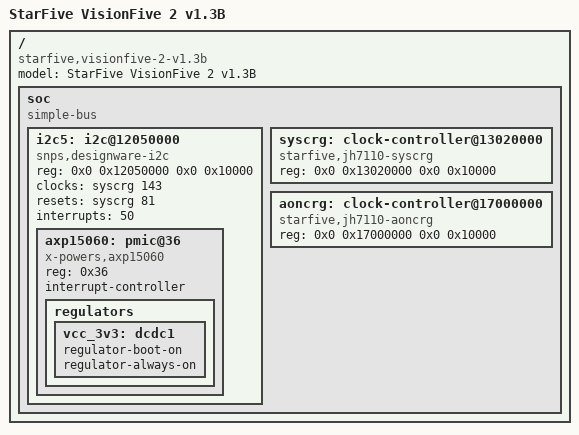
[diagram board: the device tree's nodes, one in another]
/dts-v1/;

/*
 * The PMIC's I2C bus **as mainline Linux describes it** (milestone 592
 * (radon's cold reboot dies in OpenSBI's PMIC write), provisional). NOT a dump
 * from any board: transcribed 2026-09-25 from arch/riscv/boot/dts/starfive/jh7110.dtsi (the bus,
 * `syscrg`, `aoncrg`) and jh7110-common.dtsi (the PMIC under `&i2c5`) on torvalds/linux master.
 * JH7110_SYSCLK_I2C5_APB is 143 and JH7110_SYSRST_I2C5_APB is 81 in mainline's
 * dt-bindings/{clock,reset}/starfive,jh7110-crg.h.
 *
 * The `pmic@36`'s `regulators` subtree is kept as one node so the walk has to close a grandchild
 * before the PMIC itself closes. `aoncrg` is present so a test can point at a provider that is a
 * clock controller and is not SYS (see `jh7110-pmic-bus-foreign.dts`).
 *
 * Regenerate with:
 *
 *     dtc -I dts -O dtb -o crates/machine_discovery/tests/fixtures/jh7110-pmic-bus-mainline.dtb \
 *                          crates/machine_discovery/tests/fixtures/jh7110-pmic-bus-mainline.dts
 */

/ {
	#address-cells = <2>;
	#size-cells = <2>;
	compatible = "starfive,visionfive-2-v1.3b", "starfive,jh7110";
	model = "StarFive VisionFive 2 v1.3B";

	soc {
		compatible = "simple-bus";
		#address-cells = <2>;
		#size-cells = <2>;
		ranges;

		i2c5: i2c@12050000 {
			compatible = "snps,designware-i2c";
			reg = <0x0 0x12050000 0x0 0x10000>;
			clocks = <&syscrg 143>;
			clock-names = "ref";
			resets = <&syscrg 81>;
			interrupts = <50>;
			#address-cells = <1>;
			#size-cells = <0>;
			status = "okay";

			axp15060: pmic@36 {
				compatible = "x-powers,axp15060";
				reg = <0x36>;
				interrupt-controller;
				#interrupt-cells = <1>;

				regulators {
					vcc_3v3: dcdc1 {
						regulator-boot-on;
						regulator-always-on;
					};
				};
			};
		};

		syscrg: clock-controller@13020000 {
			compatible = "starfive,jh7110-syscrg";
			reg = <0x0 0x13020000 0x0 0x10000>;
			#clock-cells = <1>;
			#reset-cells = <1>;
		};

		aoncrg: clock-controller@17000000 {
			compatible = "starfive,jh7110-aoncrg";
			reg = <0x0 0x17000000 0x0 0x10000>;
			#clock-cells = <1>;
			#reset-cells = <1>;
		};
	};
};
